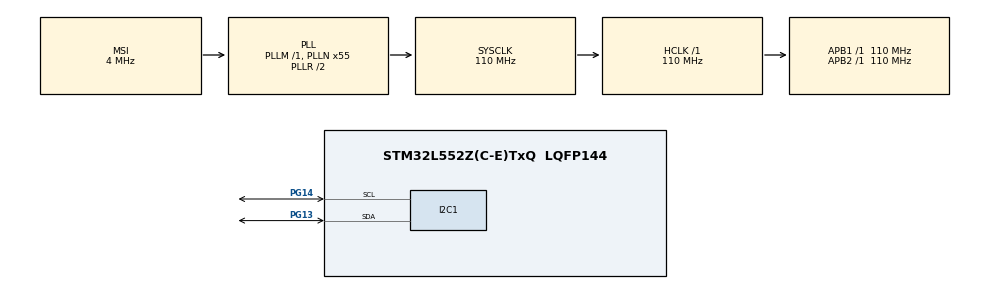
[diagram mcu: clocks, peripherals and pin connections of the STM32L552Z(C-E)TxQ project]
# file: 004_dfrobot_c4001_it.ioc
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I2C1.Timing=0x60514452
Mcu.Family=STM32L5
Mcu.Name=STM32L552Z(C-E)TxQ
Mcu.Package=LQFP144
Mcu.TrustZone=disable
NUCLEO-L552ZE-Q.BUTTON=1
NUCLEO-L552ZE-Q.LD1=true
NUCLEO-L552ZE-Q.LD2=true
NUCLEO-L552ZE-Q.LD3=true
NUCLEO-L552ZE-Q.VCP=true
NVIC.EXTI13_IRQn=true\:0\:0\:false\:false\:true\:false\:true\:true
NVIC.I2C1_ER_IRQn=true\:0\:0\:false\:false\:true\:true\:true\:true
NVIC.I2C1_EV_IRQn=true\:0\:0\:false\:false\:true\:true\:true\:true
NVIC.PriorityGroup=NVIC_PRIORITYGROUP_3
PA13\ (JTMS/SWDIO).Signal=DEBUG_JTMS-SWDIO
PA14\ (JTCK/SWCLK).Signal=DEBUG_JTCK-SWCLK
PB3\ (JTDO/TRACESWO).Signal=DEBUG_JTDO-SWO
PC14-OSC32_IN\ (PC14).Signal=RCC_OSC32_IN
PC15-OSC32_OUT\ (PC15).Signal=RCC_OSC32_OUT
PG13.Mode=I2C
PG13.Signal=I2C1_SDA
PG14.Mode=I2C
PG14.Signal=I2C1_SCL
PG7.Signal=LPUART1_TX
PG8.Signal=LPUART1_RX
ProjectManager.HeapSize=0x200
ProjectManager.StackSize=0x400
ProjectManager.TargetToolchain=STM32CubeIDE
RCC.ADCCLockSelection=RCC_ADCCLKSOURCE_SYSCLK
RCC.ADCFreq_Value=110000000
RCC.AHBFreq_Value=110000000
RCC.APB1Freq_Value=110000000
RCC.APB1TimFreq_Value=110000000
RCC.APB2Freq_Value=110000000
RCC.APB2TimFreq_Value=110000000
RCC.CK48CLockSelection=RCC_USBCLKSOURCE_HSI48
RCC.CortexFreq_Value=110000000
RCC.HCLKFreq_Value=110000000
RCC.HSE_VALUE=8000000
RCC.HSI48_VALUE=48000000
RCC.HSI_VALUE=16000000
RCC.LSE_VALUE=32768
RCC.MSI_VALUE=4000000
RCC.PLLN=55
RCC.PLLSAI1N=24
RCC.RTCClockSelection=RCC_RTCCLKSOURCE_LSE
RCC.SYSCLKFreq_VALUE=110000000
RCC.SYSCLKSource=RCC_SYSCLKSOURCE_PLLCLK
RCC.USBFreq_Value=48000000
RCC.VCOOutputFreq_Value=220000000
VP_ICACHE_VS_ICACHE.Mode=DirectMappedCache
VP_NUCLEO-L552ZE-Q_VS_BSP_COMMON.Mode=COMMON
VP_PWR_VS_DBSignals.Mode=DisableDeadBatterySignals
VP_PWR_VS_SECSignals.Mode=Security/Privilege
board=NUCLEO-L552ZE-Q

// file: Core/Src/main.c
/* USER CODE BEGIN Header */
/**
  ******************************************************************************
  * @file           : main.c
  * @brief          : Main program body
  ******************************************************************************
  * @attention
  *
  * Copyright (c) 2025 STMicroelectronics.
  * All rights reserved.
  *
  * This software is licensed under terms that can be found in the LICENSE file
  * in the root directory of this software component.
  * If no LICENSE file comes with this software, it is provided AS-IS.
  *
  ******************************************************************************
  */
/* USER CODE END Header */
#include "main.h"

/* USER CODE BEGIN Includes */
#include "dfrobot_c4001.h"
#include <stdio.h>
/* USER CODE END Includes */

COM_InitTypeDef BspCOMInit;
I2C_HandleTypeDef hi2c1;

/* USER CODE BEGIN PV */
C4001_Handle_t c4001_dev;

/* I2C interrupt state variables (defined in dfrobot_c4001.c) */
extern volatile uint8_t i2c_state;
extern volatile HAL_StatusTypeDef i2c_result;
/* USER CODE END PV */

void SystemClock_Config(void);
static void MX_GPIO_Init(void);
static void MX_I2C1_Init(void);
static void MX_ICACHE_Init(void);
/* USER CODE BEGIN PFP */
void C4001_Example_I2C(void);
void C4001_Example_UART(void);
void C4001_Example_Advanced(void);
/* USER CODE END PFP */

int main(void)
{

  /* MCU Configuration--------------------------------------------------------*/

  /* Reset of all peripherals, Initializes the Flash interface and the Systick. */
  HAL_Init();

  /* Configure the system clock */
  SystemClock_Config();

  /* Initialize all configured peripherals */
  MX_GPIO_Init();
  MX_I2C1_Init();
  MX_ICACHE_Init();

  /* Initialize leds */
  BSP_LED_Init(LED_GREEN);
  BSP_LED_Init(LED_BLUE);
  BSP_LED_Init(LED_RED);

  /* Initialize USER push-button, will be used to trigger an interrupt each time it's pressed.*/
  BSP_PB_Init(BUTTON_USER, BUTTON_MODE_EXTI);

  /* Initialize COM1 port (115200, 8 bits (7-bit data + 1 stop bit), no parity */
  BspCOMInit.BaudRate   = 115200;
  BspCOMInit.WordLength = COM_WORDLENGTH_8B;
  BspCOMInit.StopBits   = COM_STOPBITS_1;
  BspCOMInit.Parity     = COM_PARITY_NONE;
  BspCOMInit.HwFlowCtl  = COM_HWCONTROL_NONE;
  if (BSP_COM_Init(COM1, &BspCOMInit) != BSP_ERROR_NONE)
  {
    Error_Handler();
  }

  /* Infinite loop */
  /* USER CODE BEGIN WHILE */
  C4001_Example_I2C();
//  C4001_Example_Advanced();

  while (1)
  {

    /* USER CODE END WHILE */

  }
}

void SystemClock_Config(void)
{
  RCC_OscInitTypeDef RCC_OscInitStruct = {0};
  RCC_ClkInitTypeDef RCC_ClkInitStruct = {0};

  /** Configure the main internal regulator output voltage
  */
  if (HAL_PWREx_ControlVoltageScaling(PWR_REGULATOR_VOLTAGE_SCALE0) != HAL_OK)
  {
    Error_Handler();
  }

  /** Initializes the RCC Oscillators according to the specified parameters
  * in the RCC_OscInitTypeDef structure.
  */
  RCC_OscInitStruct.OscillatorType = RCC_OSCILLATORTYPE_MSI;
  RCC_OscInitStruct.MSIState = RCC_MSI_ON;
  RCC_OscInitStruct.MSICalibrationValue = RCC_MSICALIBRATION_DEFAULT;
  RCC_OscInitStruct.MSIClockRange = RCC_MSIRANGE_6;
  RCC_OscInitStruct.PLL.PLLState = RCC_PLL_ON;
  RCC_OscInitStruct.PLL.PLLSource = RCC_PLLSOURCE_MSI;
  RCC_OscInitStruct.PLL.PLLM = 1;
  RCC_OscInitStruct.PLL.PLLN = 55;
  RCC_OscInitStruct.PLL.PLLP = RCC_PLLP_DIV7;
  RCC_OscInitStruct.PLL.PLLQ = RCC_PLLQ_DIV2;
  RCC_OscInitStruct.PLL.PLLR = RCC_PLLR_DIV2;
  if (HAL_RCC_OscConfig(&RCC_OscInitStruct) != HAL_OK)
  {
    Error_Handler();
  }

  /** Initializes the CPU, AHB and APB buses clocks
  */
  RCC_ClkInitStruct.ClockType = RCC_CLOCKTYPE_HCLK|RCC_CLOCKTYPE_SYSCLK
                              |RCC_CLOCKTYPE_PCLK1|RCC_CLOCKTYPE_PCLK2;
  RCC_ClkInitStruct.SYSCLKSource = RCC_SYSCLKSOURCE_PLLCLK;
  RCC_ClkInitStruct.AHBCLKDivider = RCC_SYSCLK_DIV1;
  RCC_ClkInitStruct.APB1CLKDivider = RCC_HCLK_DIV1;
  RCC_ClkInitStruct.APB2CLKDivider = RCC_HCLK_DIV1;

  if (HAL_RCC_ClockConfig(&RCC_ClkInitStruct, FLASH_LATENCY_5) != HAL_OK)
  {
    Error_Handler();
  }
}

static void MX_I2C1_Init(void)
{

  hi2c1.Instance = I2C1;
  hi2c1.Init.Timing = 0x60514452;
  hi2c1.Init.OwnAddress1 = 0;
  hi2c1.Init.AddressingMode = I2C_ADDRESSINGMODE_7BIT;
  hi2c1.Init.DualAddressMode = I2C_DUALADDRESS_DISABLE;
  hi2c1.Init.OwnAddress2 = 0;
  hi2c1.Init.OwnAddress2Masks = I2C_OA2_NOMASK;
  hi2c1.Init.GeneralCallMode = I2C_GENERALCALL_DISABLE;
  hi2c1.Init.NoStretchMode = I2C_NOSTRETCH_DISABLE;
  if (HAL_I2C_Init(&hi2c1) != HAL_OK)
  {
    Error_Handler();
  }

  /** Configure Analogue filter
  */
  if (HAL_I2CEx_ConfigAnalogFilter(&hi2c1, I2C_ANALOGFILTER_ENABLE) != HAL_OK)
  {
    Error_Handler();
  }

  /** Configure Digital filter
  */
  if (HAL_I2CEx_ConfigDigitalFilter(&hi2c1, 0) != HAL_OK)
  {
    Error_Handler();
  }

}

static void MX_ICACHE_Init(void)
{

  /** Enable instruction cache in 1-way (direct mapped cache)
  */
  if (HAL_ICACHE_ConfigAssociativityMode(ICACHE_1WAY) != HAL_OK)
  {
    Error_Handler();
  }
  if (HAL_ICACHE_Enable() != HAL_OK)
  {
    Error_Handler();
  }

}

static void MX_GPIO_Init(void)
{

  /* GPIO Ports Clock Enable */
  __HAL_RCC_GPIOC_CLK_ENABLE();
  __HAL_RCC_GPIOA_CLK_ENABLE();
  __HAL_RCC_GPIOG_CLK_ENABLE();
  HAL_PWREx_EnableVddIO2();
  __HAL_RCC_GPIOB_CLK_ENABLE();

}

/* USER CODE BEGIN 4 */

/**
 * @brief I2C Memory Tx Transfer completed callback
 * @param hi2c: Pointer to I2C handle
 */
void HAL_I2C_MemTxCpltCallback(I2C_HandleTypeDef *hi2c)
{
	if (hi2c->Instance == I2C1)
	{
		i2c_state = 0; // I2C_STATE_READY
		i2c_result = HAL_OK;
	}
}

/**
 * @brief I2C Memory Rx Transfer completed callback
 * @param hi2c: Pointer to I2C handle
 */
void HAL_I2C_MemRxCpltCallback(I2C_HandleTypeDef *hi2c)
{
	if (hi2c->Instance == I2C1)
	{
		i2c_state = 0; // I2C_STATE_READY
		i2c_result = HAL_OK;
	}
}

/**
 * @brief I2C error callback
 * @param hi2c: Pointer to I2C handle
 */
void HAL_I2C_ErrorCallback(I2C_HandleTypeDef *hi2c)
{
	if (hi2c->Instance == I2C1)
	{
		i2c_state = 3; // I2C_STATE_ERROR
		i2c_result = HAL_ERROR;
	}
}

void C4001_Example_I2C(void)
{
	// init c4001
	if (C4001_Init_I2C(&c4001_dev, &hi2c1, C4001_I2C_ADDR_1) != HAL_OK)
	{
		printf("C4001 I2C initialization failed!\r\n");
		Error_Handler();
	}
	printf("C4001 I2C initialized successfully!\r\n");

	// get sensor status
	C4001_SensorStatus_t status = C4001_GetStatus(&c4001_dev);
	printf("Status: work=%d, mode=%d, init=%d\r\n",
			status.work_status, status.work_mode, status.init_status);

	// start sensor if not running
	if (!status.work_status)
	{
		C4001_SetSensor(&c4001_dev, C4001_CMD_START_SENSOR);
		printf("Sensor started\r\n");
	}

	// set to presence detection mode
	if (C4001_SetSensorMode(&c4001_dev, C4001_MODE_EXIST))
	{
		printf("Set to presence detection mode\r\n");
	}

	// configure sensitivity
	C4001_SetTrigSensitivity(&c4001_dev, 7);  // 0-9, higher = more sensitive
	C4001_SetKeepSensitivity(&c4001_dev, 5);
	printf("Sensitivity configured\r\n");

	// configure detection range
	C4001_SetDetectionRange(&c4001_dev, 50, 500, 300);  // min, max, trig in cm
	printf("Range: 50cm to 500cm, trigger at 300cm\r\n");

	// configure delays
	C4001_SetDelay(&c4001_dev, 10, 100);  // trig=0.1s, keep=50s
	printf("Delay configured\r\n");

	printf("\r\nStarting motion detection...\r\n");
	while (1)
	{
		if (C4001_MotionDetection(&c4001_dev))
		{
			printf("Motion detected!\r\n");
		}
		else
		{
			printf("No motion detected\r\n");
		}
		HAL_Delay(100);
	}
}

void C4001_Example_Advanced(void)
{
	// init c4001
	if (C4001_Init_I2C(&c4001_dev, &hi2c1, C4001_I2C_ADDR_1) != HAL_OK)
	{
		printf("C4001 I2C initialization failed!\r\n");
		Error_Handler();
	}
	printf("C4001 I2C initialized successfully!\r\n");

    // Read current configuration
    uint8_t trig_sens = C4001_GetTrigSensitivity(&c4001_dev);
    uint8_t keep_sens = C4001_GetKeepSensitivity(&c4001_dev);
    uint8_t trig_delay = C4001_GetTrigDelay(&c4001_dev);
    uint16_t keep_timeout = C4001_GetKeepTimeout(&c4001_dev);
    uint16_t min_range = C4001_GetMinRange(&c4001_dev);
    uint16_t max_range = C4001_GetMaxRange(&c4001_dev);
    uint16_t trig_range = C4001_GetTrigRange(&c4001_dev);

    printf("\r\n--- Current Configuration ---\r\n");
    printf("Trigger Sensitivity: %d\r\n", trig_sens);
    printf("Keep Sensitivity: %d\r\n", keep_sens);
    printf("Trigger Delay: %d (x0.01s)\r\n", trig_delay);
    printf("Keep Timeout: %d (x0.5s)\r\n", keep_timeout);
    printf("Min Range: %d cm\r\n", min_range);
    printf("Max Range: %d cm\r\n", max_range);
    printf("Trigger Range: %d cm\r\n", trig_range);

    // Configure PWM output
    C4001_SetPwm(&c4001_dev, 10, 90, 20);  // 10% no target, 90% target, 1.28s transition
    C4001_PwmData_t pwm = C4001_GetPwm(&c4001_dev);
    printf("PWM: %d%% -> %d%% over %dms\r\n", pwm.pwm1, pwm.pwm2, pwm.timer * 64);

    // Configure I/O polarity
    C4001_SetIoPolarity(&c4001_dev, 1);  // High when target detected
    printf("I/O Polarity: %d\r\n", C4001_GetIoPolarity(&c4001_dev));

    // Enable micro-motion detection
    C4001_SetFrettingDetection(&c4001_dev, C4001_SWITCH_ON);
    printf("Micro-motion: %d\r\n", C4001_GetFrettingDetection(&c4001_dev));

    // Save configuration
    C4001_SetSensor(&c4001_dev, C4001_CMD_SAVE_PARAMS);
    printf("Configuration saved to sensor\r\n");
}
/* USER CODE END 4 */

void Error_Handler(void)
{
  /* USER CODE BEGIN Error_Handler_Debug */
  /* User can add his own implementation to report the HAL error return state */

  __disable_irq();
  while (1)
  {
	  BSP_LED_Toggle(LED_RED);
  }
  /* USER CODE END Error_Handler_Debug */
}
